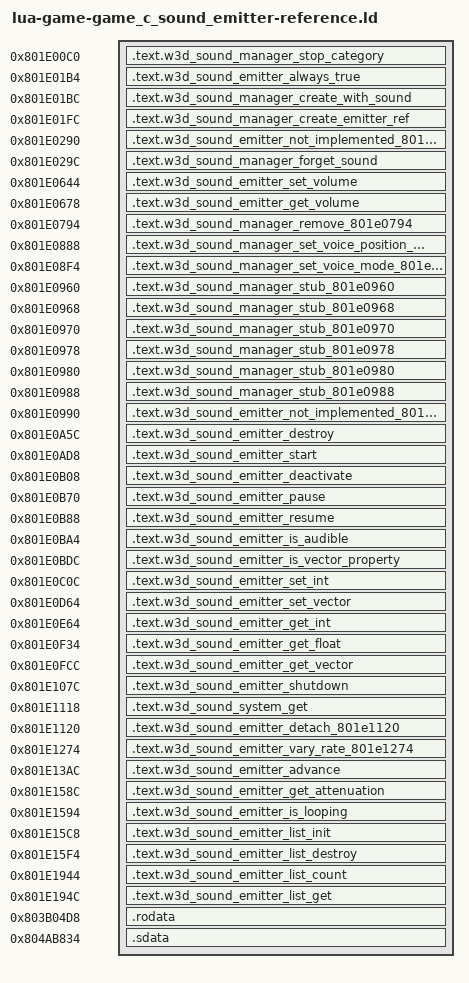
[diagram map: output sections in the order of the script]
/* Generated reference-only placements. All bodies are source-built. */
OUTPUT_FORMAT("elf32-powerpc")
OUTPUT_ARCH(powerpc)
ENTRY(w3d_sound_manager_stop_category)
_SDA_BASE_ = 0x804b2540;
_SDA2_BASE_ = 0x804c2540;
w3d_actor_member_delete_backend = 0x801fe1f8;
w3d_actor_node_destroy = 0x80210990;
w3d_channel_status_803229bc = 0x803229bc;
w3d_f32_803b0484 = 0x803b0484;
w3d_f32_803b0488 = 0x803b0488;
w3d_f32_803b04d0 = 0x803b04d0;
w3d_memmove_802eee50 = 0x802eee50;
w3d_rand_802ee7dc = 0x802ee7dc;
w3d_sound_emitter_attach_801e117c = 0x801e117c;
w3d_sound_emitter_base_vtable_80416a90 = 0x80416a90;
w3d_sound_emitter_vtable_80416d20 = 0x80416d20;
w3d_sound_get_base_rate_801df104 = 0x801df104;
w3d_sound_get_category_801df288 = 0x801df288;
w3d_sound_get_position_at_801df23c = 0x801df23c;
w3d_sound_is_looping_801df1ac = 0x801df1ac;
w3d_sound_manager_create_emitter_801e0680 = 0x801e0680;
w3d_sound_voice_release_801e4f38 = 0x801e4f38;
w3d_str_803b04bc = 0x803b04bc;
w3d_strcmp_802ef234 = 0x802ef234;
SECTIONS {
  .text.w3d_sound_manager_stop_category 0x801e00c0 : { *(.text.w3d_sound_manager_stop_category) }
  .text.w3d_sound_emitter_always_true 0x801e01b4 : { *(.text.w3d_sound_emitter_always_true) }
  .text.w3d_sound_manager_create_with_sound 0x801e01bc : { *(.text.w3d_sound_manager_create_with_sound) }
  .text.w3d_sound_manager_create_emitter_ref 0x801e01fc : { *(.text.w3d_sound_manager_create_emitter_ref) }
  .text.w3d_sound_emitter_not_implemented_801e0290 0x801e0290 : { *(.text.w3d_sound_emitter_not_implemented_801e0290) }
  .text.w3d_sound_manager_forget_sound 0x801e029c : { *(.text.w3d_sound_manager_forget_sound) }
  .text.w3d_sound_emitter_set_volume 0x801e0644 : { *(.text.w3d_sound_emitter_set_volume) }
  .text.w3d_sound_emitter_get_volume 0x801e0678 : { *(.text.w3d_sound_emitter_get_volume) }
  .text.w3d_sound_manager_remove_801e0794 0x801e0794 : { *(.text.w3d_sound_manager_remove_801e0794) }
  .text.w3d_sound_manager_set_voice_position_801e0888 0x801e0888 : { *(.text.w3d_sound_manager_set_voice_position_801e0888) }
  .text.w3d_sound_manager_set_voice_mode_801e08f4 0x801e08f4 : { *(.text.w3d_sound_manager_set_voice_mode_801e08f4) }
  .text.w3d_sound_manager_stub_801e0960 0x801e0960 : { *(.text.w3d_sound_manager_stub_801e0960) }
  .text.w3d_sound_manager_stub_801e0968 0x801e0968 : { *(.text.w3d_sound_manager_stub_801e0968) }
  .text.w3d_sound_manager_stub_801e0970 0x801e0970 : { *(.text.w3d_sound_manager_stub_801e0970) }
  .text.w3d_sound_manager_stub_801e0978 0x801e0978 : { *(.text.w3d_sound_manager_stub_801e0978) }
  .text.w3d_sound_manager_stub_801e0980 0x801e0980 : { *(.text.w3d_sound_manager_stub_801e0980) }
  .text.w3d_sound_manager_stub_801e0988 0x801e0988 : { *(.text.w3d_sound_manager_stub_801e0988) }
  .text.w3d_sound_emitter_not_implemented_801e0990 0x801e0990 : { *(.text.w3d_sound_emitter_not_implemented_801e0990) }
  .text.w3d_sound_emitter_destroy 0x801e0a5c : { *(.text.w3d_sound_emitter_destroy) }
  .text.w3d_sound_emitter_start 0x801e0ad8 : { *(.text.w3d_sound_emitter_start) }
  .text.w3d_sound_emitter_deactivate 0x801e0b08 : { *(.text.w3d_sound_emitter_deactivate) }
  .text.w3d_sound_emitter_pause 0x801e0b70 : { *(.text.w3d_sound_emitter_pause) }
  .text.w3d_sound_emitter_resume 0x801e0b88 : { *(.text.w3d_sound_emitter_resume) }
  .text.w3d_sound_emitter_is_audible 0x801e0ba4 : { *(.text.w3d_sound_emitter_is_audible) }
  .text.w3d_sound_emitter_is_vector_property 0x801e0bdc : { *(.text.w3d_sound_emitter_is_vector_property) }
  .text.w3d_sound_emitter_set_int 0x801e0c0c : { *(.text.w3d_sound_emitter_set_int) }
  .text.w3d_sound_emitter_set_vector 0x801e0d64 : { *(.text.w3d_sound_emitter_set_vector) }
  .text.w3d_sound_emitter_get_int 0x801e0e64 : { *(.text.w3d_sound_emitter_get_int) }
  .text.w3d_sound_emitter_get_float 0x801e0f34 : { *(.text.w3d_sound_emitter_get_float) }
  .text.w3d_sound_emitter_get_vector 0x801e0fcc : { *(.text.w3d_sound_emitter_get_vector) }
  .text.w3d_sound_emitter_shutdown 0x801e107c : { *(.text.w3d_sound_emitter_shutdown) }
  .text.w3d_sound_system_get 0x801e1118 : { *(.text.w3d_sound_system_get) }
  .text.w3d_sound_emitter_detach_801e1120 0x801e1120 : { *(.text.w3d_sound_emitter_detach_801e1120) }
  .text.w3d_sound_emitter_vary_rate_801e1274 0x801e1274 : { *(.text.w3d_sound_emitter_vary_rate_801e1274) }
  .text.w3d_sound_emitter_advance 0x801e13ac : { *(.text.w3d_sound_emitter_advance) }
  .text.w3d_sound_emitter_get_attenuation 0x801e158c : { *(.text.w3d_sound_emitter_get_attenuation) }
  .text.w3d_sound_emitter_is_looping 0x801e1594 : { *(.text.w3d_sound_emitter_is_looping) }
  .text.w3d_sound_emitter_list_init 0x801e15c8 : { *(.text.w3d_sound_emitter_list_init) }
  .text.w3d_sound_emitter_list_destroy 0x801e15f4 : { *(.text.w3d_sound_emitter_list_destroy) }
  .text.w3d_sound_emitter_list_count 0x801e1944 : { *(.text.w3d_sound_emitter_list_count) }
  .text.w3d_sound_emitter_list_get 0x801e194c : { *(.text.w3d_sound_emitter_list_get) }
  .rodata 0x803b04d8 : { *(.rodata) }
  .sdata 0x804ab834 (NOLOAD) : {
    . = 0x0; w3d_sound_system_804ab834 = .;
    . += 1; }
  /DISCARD/ : { *(.text*) *(.rodata*) *(.data*) *(.bss*) *(.sdata*) *(.sbss*) *(.comment) }
}
